# bcm2711_lpa register map
Vendor: BROADCOM; Series: BCM2711; File version: A
CPU: CA72 r0p0, little endian, MPU, FPU, 2 interrupt priority bits
Registers are 32-bit, read-write, reset 0x0 unless marked. A register's access mark holds for its fields unless they carry their own. Offsets are from the block's base; [hi:lo] are bit positions; {n}, {i} and the like mark numbered series; 'fields as' and 'values as' point back to an identical list.

## DMA
Base 0xFE007000
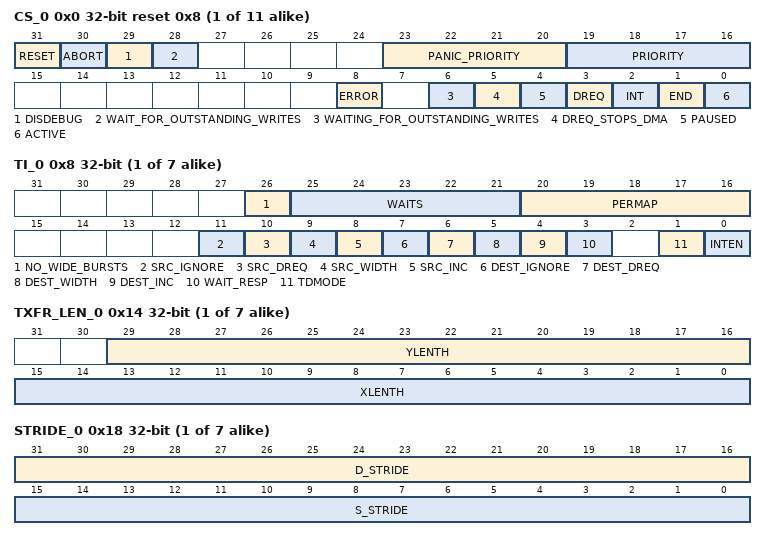
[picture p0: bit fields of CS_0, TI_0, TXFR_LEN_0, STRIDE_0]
{0x0+0x100*i} CS_{i} access per field reset 0x8 (i=0..10) — DMA Control and Status register contains the main control and status bits for this DMA channel
  [31] RESET rw write-1-clears — DMA Channel Reset
  [30] ABORT rw write-1-clears — Abort DMA
  [29] DISDEBUG rw — Disable Debug Pause Signal
  [28] WAIT_FOR_OUTSTANDING_WRITES rw
  [23:20] PANIC_PRIORITY rw — AXI Panic Priority Level
  [19:16] PRIORITY rw — AXI Priority Level
  [8] ERROR ro — DMA Error
  [6] WAITING_FOR_OUTSTANDING_WRITES ro — The DMA is Waiting for the Last Write to be Received
  [5] DREQ_STOPS_DMA ro — DMA Paused by DREQ State
  [4] PAUSED ro — DMA Paused State
  [3] DREQ ro — DREQ State
  [2] INT rw write-1-clears — Interrupt Status
  [1] END rw write-1-clears — End Flag
  [0] ACTIVE rw — Activate the DMA
{0x4+0x100*i} CONBLK_AD_{i} (i=0..10) — DMA Control Block Address register
  [31:0] SCB_ADDR — Control Block Address
{0x8+0x100*i} TI_{i} (i=0..6) — DMA Transfer Information
  [26] NO_WIDE_BURSTS — Dont do wide writes as a 2 beat burst
  [25:21] WAITS — Add Wait Cycles
  [20:16] PERMAP — Peripheral Mapping
  [11] SRC_IGNORE — Ignore Reads
  [10] SRC_DREQ — Control Source Reads with DREQ
  [9] SRC_WIDTH — Source Transfer Width
  [8] SRC_INC — Source Address Increment
  [7] DEST_IGNORE — Ignore Writes
  [6] DEST_DREQ — Control Destination Writes with DREQ
  [5] DEST_WIDTH — Destination Transfer Width
  [4] DEST_INC — Destination Address Increment
  [3] WAIT_RESP — Wait for a Write Response
  [1] TDMODE — 2D Mode
  [0] INTEN — Interrupt Enable
{0xC+0x100*i} SOURCE_AD_{i} (i=0..10) — DMA Source Address
  [31:0] S_ADDR
{0x10+0x100*i} DEST_AD_{i} (i=0..10) — DMA Destination Address
  [31:0] D_ADDR
{0x14+0x100*i} TXFR_LEN_{i} (i=0..6) — DMA Transfer Length
  [29:16] YLENTH — When in 2D mode, This is the Y transfer length, indicating how many xlength transfers are performed, when in normal linear mode this becomes the top bits of the XLENGTH
  [15:0] XLENTH — Transfer Length in bytes
{0x18+0x100*i} STRIDE_{i} (i=0..6) — DMA 2D Stride
  [31:16] D_STRIDE — Destination Stride (2D Mode)
  [15:0] S_STRIDE — Source Stride (2D Mode)
{0x1C+0x100*i} NEXTCONBK_{i} (i=0..10) — DMA Next Control Block Address
  [31:0] ADDR — Address of next CB for chained DMA operations
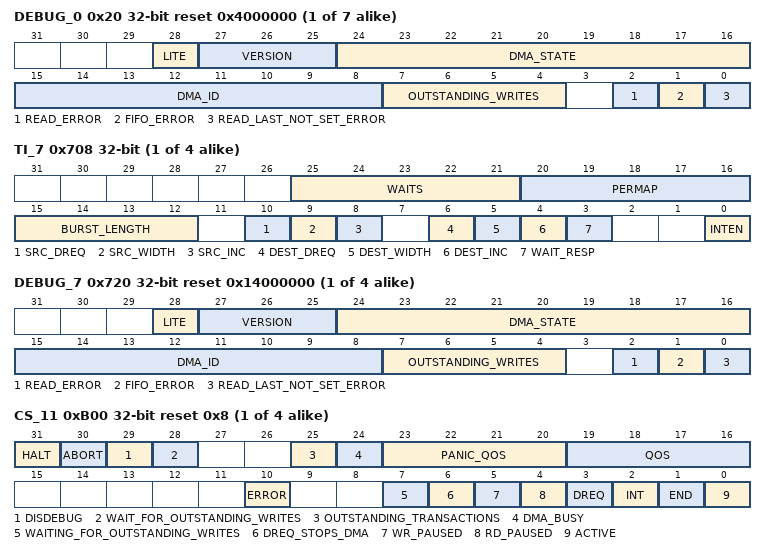
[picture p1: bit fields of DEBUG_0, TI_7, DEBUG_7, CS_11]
{0x20+0x100*i} DEBUG_{i} access per field reset 0x4000000 (i=0..6) — DMA4 Debug register
  [28] LITE ro — DMA Lite
  [27:25] VERSION ro — DMA Version
  [24:16] DMA_STATE ro — DMA State Machine State
  [15:8] DMA_ID ro
  [7:4] OUTSTANDING_WRITES ro — DMA Outstanding Writes Counter
  [2] READ_ERROR rw write-1-clears — Slave Read Response Error
  [1] FIFO_ERROR rw write-1-clears
  [0] READ_LAST_NOT_SET_ERROR rw write-1-clears
{0x8+0x100*i} TI_{i} (i=7..10) — DMA Lite Transfer Information
  [25:21] WAITS — Add Wait Cycles
  [20:16] PERMAP — Peripheral Mapping
  [15:12] BURST_LENGTH — Burst Transfer Length
  [10] SRC_DREQ — Control Source Reads with DREQ
  [9] SRC_WIDTH — Source Transfer Width
  [8] SRC_INC — Source Address Increment
  [6] DEST_DREQ — Control Destination Writes with DREQ
  [5] DEST_WIDTH — Destination Transfer Width
  [4] DEST_INC — Destination Address Increment
  [3] WAIT_RESP — Wait for a Write Response
  [0] INTEN — Interrupt Enable
{0x14+0x100*i} TXFR_LEN_{i} (i=7..10) — DMA Lite Transfer Length
  [15:0] XLENTH — Transfer Length
{0x20+0x100*i} DEBUG_{i} access per field reset 0x14000000 (i=7..10) — DMA4 Debug register
  fields as DEBUG_0
{0x0+0x100*i} CS_{i} access per field reset 0x8 (i=11..14) — DMA4 Control and Status register contains the main control and status bits for this DMA4 channel
  [31] HALT rw write-1-clears — Writing a 1 to this bit will cleanly halt the current DMA4 transfer
  [30] ABORT rw write-1-clears — Abort DMA4
  [29] DISDEBUG rw — Disable Debug Pause Signal
  [28] WAIT_FOR_OUTSTANDING_WRITES rw
  [25] OUTSTANDING_TRANSACTIONS ro — Indicates that there are outstanding AXI transfers
  [24] DMA_BUSY ro — Indicates the DMA4 is BUSY
  [23:20] PANIC_QOS rw — AXI Panic QOS Level
  [19:16] QOS rw — AXI QOS Level
  [10] ERROR ro — DMA4 Error
  [7] WAITING_FOR_OUTSTANDING_WRITES ro — The DMA4 is Waiting for all the Write Response to be returned
  [6] DREQ_STOPS_DMA ro — DMA4 Paused by DREQ State
  [5] WR_PAUSED ro — DMA4 Write Paused State
  [4] RD_PAUSED ro — DMA4 Read Paused State
  [3] DREQ ro — DREQ State
  [2] INT rw write-1-clears — Interrupt Status
  [1] END rw write-1-clears — End Flag
  [0] ACTIVE rw — Activate the DMA4
{0x4+0x100*i} CB_{i} (i=11..14) — DMA4 Control Block Address register
  [31:0] ADDR — Control Block Address
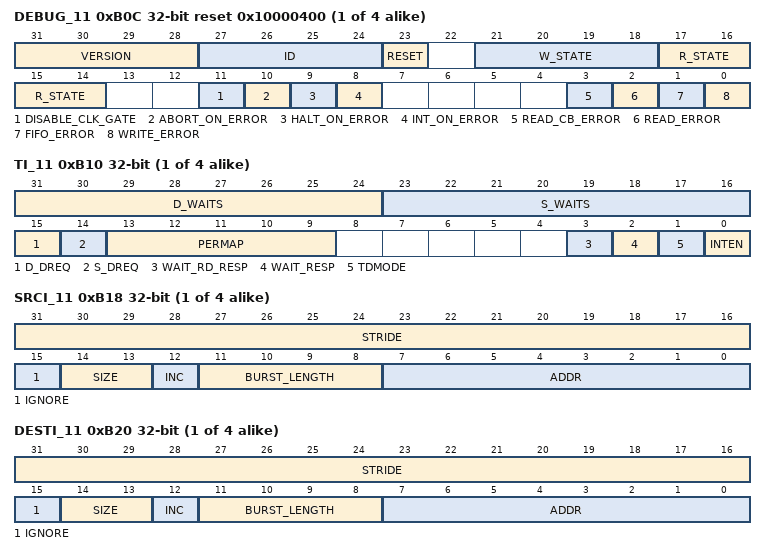
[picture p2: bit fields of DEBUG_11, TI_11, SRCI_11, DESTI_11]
{0xC+0x100*i} DEBUG_{i} access per field reset 0x10000400 (i=11..14) — DMA4 Debug register
  [31:28] VERSION ro — DMA Version
  [27:24] ID ro
  [23] RESET rw write-1-clears — DMA Reset
  [21:18] W_STATE ro — Write State Machine State
  [17:14] R_STATE ro — Read State Machine State
  [11] DISABLE_CLK_GATE rw — Disable the clock gating logic
  [10] ABORT_ON_ERROR rw — Instruct the DMA4 to ABORT if it detects an error
  [9] HALT_ON_ERROR rw — Instruct the DMA4 to HALT if it detects an error
  [8] INT_ON_ERROR rw — Generate an interrupt if an error is detected
  [3] READ_CB_ERROR ro — Slave Read Response Error During Control Block Read
  [2] READ_ERROR ro — Slave Read Response Error
  [1] FIFO_ERROR ro
  [0] WRITE_ERROR ro — Slave Write Response Error
{0x10+0x100*i} TI_{i} (i=11..14) — DMA4 Transfer Information
  [31:24] D_WAITS — Write Wait Cycles
  [23:16] S_WAITS — Read Wait Cycles
  [15] D_DREQ — Control Destination Writes with DREQ
  [14] S_DREQ — Control Source Reads with DREQ
  [13:9] PERMAP — Peripheral Mapping
  [3] WAIT_RD_RESP — Wait for a Read Response
  [2] WAIT_RESP — Wait for a Write Response
  [1] TDMODE — Perform a 2D transfer instead of a normal linear transfer
  [0] INTEN — Interrupt Enable
{0x14+0x100*i} SRC_{i} (i=11..14) — Lower 32 bits of the DMA4 Source Address
  [31:0] ADDR — Lower bits of the Source Address
{0x18+0x100*i} SRCI_{i} (i=11..14) — DMA4 Source Information
  [31:16] STRIDE — Source Stride
  [15] IGNORE — Ignore Reads
  [14:13] SIZE — Source Transfer Width
  [12] INC — Increment the Source Address
  [11:8] BURST_LENGTH — Burst Transfer Length
  [7:0] ADDR — High Bits of the Source Address
{0x1C+0x100*i} DEST_{i} (i=11..14) — Lower 32 bits of the DMA4 Destination Address
  [31:0] ADDR — Destination Address
{0x20+0x100*i} DESTI_{i} (i=11..14) — DMA4 Destination Information
  [31:16] STRIDE — Destination Stride
  [15] IGNORE — Ignore Reads
  [14:13] SIZE — Destination Transfer Width
  [12] INC — Increment the Destination Address
  [11:8] BURST_LENGTH — Burst Transfer Length
  [7:0] ADDR — High Bits of the Destination Address
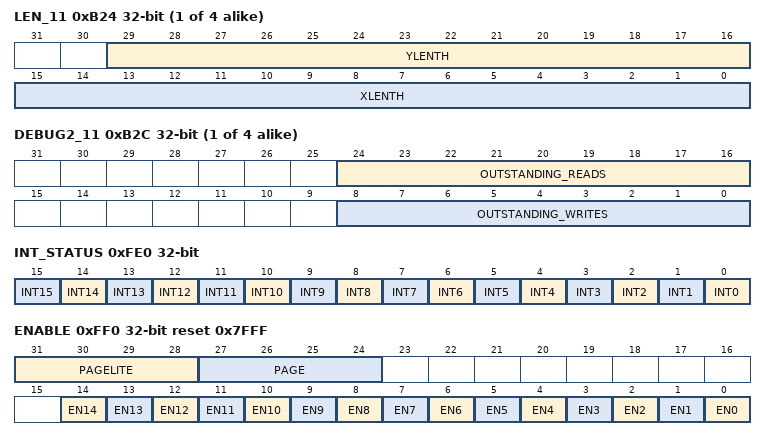
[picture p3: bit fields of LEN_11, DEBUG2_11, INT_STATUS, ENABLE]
{0x24+0x100*i} LEN_{i} (i=11..14) — DMA4 Transfer Length
  fields as TXFR_LEN_0
{0x28+0x100*i} NEXT_CB_{i} (i=11..14) — DMA4 Next Control Block Address
  [31:0] ADDR — Address of next CB for chained DMA operations
{0x2C+0x100*i} DEBUG2_{i} ro (i=11..14) — DMA4 Debug2 register
  [24:16] OUTSTANDING_READS — Outstanding read Words Count
  [8:0] OUTSTANDING_WRITES — Outstanding Write Response Count
0xFE0 INT_STATUS ro — Interrupt status of each DMA engine
  [n] INT{n} (n=0..15) — Interrupt status of DMA engine {n}
0xFF0 ENABLE reset 0x7FFF — Global enable bits for each channel
  [31:28] PAGELITE — Set the 1G SDRAM ram page that the 30-bit DMA llite engines (DMA7-10) will access when addressing the 1G uncached range C000_0000->ffff_ffff
  [27:24] PAGE — Set the 1G SDRAM ram page that the 30-bit DMA engines (DMA0-6) will access when addressing the 1G uncached range C000_0000->ffff_ffff
  [n] EN{n} (n=0..14) — Enable dma engine {n}
